# LargeDummyDevice register map
File version: 1.0
Registers are 32-bit, read-write, no defined reset value unless marked. A register's access mark holds for its fields unless they carry their own. Offsets are from the block's base; [hi:lo] are bit positions.

## PERIPHERAL_94
Base 0x4005D000
0x04 REG_1 — Register 1
  [35:31] FIELD_3, [33:31] FIELD_19, [30:28] FIELD_22, [30:27] FIELD_1, [28:26] FIELD_12, [28:26] FIELD_14, [28:25] FIELD_15, [26:23] FIELD_18, [27:23] FIELD_24, [22:20] FIELD_7, [22:19] FIELD_4, [23:19] FIELD_16, [20:16] FIELD_17, [17:13] FIELD_9, [14:12] FIELD_5, [15:12] FIELD_21, [12] FIELD_23, [15:11] FIELD_8, [14:10] FIELD_6, [11:8] FIELD_20, [10:7] FIELD_2, [5:4] FIELD_10, [7:4] FIELD_13, [7:3] FIELD_11
0x08 REG_2 — Register 2
  [32:30] FIELD_9, [31:29] FIELD_19, [29:28] FIELD_6, [30:28] FIELD_20, [29:25] FIELD_14, [24] FIELD_13, [24:23] FIELD_4, [24:23] FIELD_12, [27:23] FIELD_15, [25:22] FIELD_1, [24:21] FIELD_18, [20] FIELD_5, [20:19] FIELD_17, [17:16] FIELD_3, [15:14] FIELD_21, [7:6] FIELD_11, [6] FIELD_16, [6:5] FIELD_7, [4] FIELD_10, [1] FIELD_8, [2:0] FIELD_2
0x0C REG_3 — Register 3
  [29] FIELD_9, [29:28] FIELD_6, [29:26] FIELD_5, [25:24] FIELD_3, [24] FIELD_13, [23:22] FIELD_10, [25:22] FIELD_15, [22:21] FIELD_18, [17] FIELD_7, [17] FIELD_21, [17:16] FIELD_8, [18:16] FIELD_19, [15:14] FIELD_16, [12:10] FIELD_1, [14:10] FIELD_2, [10] FIELD_11, [10:6] FIELD_20, [5:3] FIELD_4, [3] FIELD_12, [4:3] FIELD_14, [2:0] FIELD_17
0x10 REG_4 — Register 4
  [33:31] FIELD_13, [30] FIELD_7, [29:27] FIELD_4, [28:26] FIELD_3, [25:23] FIELD_14, [22] FIELD_12, [20:19] FIELD_16, [17] FIELD_2, [18:14] FIELD_5, [18:14] FIELD_9, [14] FIELD_15, [14:12] FIELD_8, [13:9] FIELD_6, [12:9] FIELD_18, [8:6] FIELD_17, [5:3] FIELD_1, [4:2] FIELD_10, [0] FIELD_11
0x14 REG_5 — Register 5
  [31] FIELD_6, [28] FIELD_18, [29:27] FIELD_21, [27:26] FIELD_4, [27:26] FIELD_22, [25:24] FIELD_8, [28:24] FIELD_23, [24] FIELD_25, [23:22] FIELD_7, [25:21] FIELD_9, [24:20] FIELD_14, [23:20] FIELD_16, [23:20] FIELD_17, [22:20] FIELD_20, [22:19] FIELD_19, [21:18] FIELD_13, [19:18] FIELD_24, [21:17] FIELD_10, [20:17] FIELD_12, [16:13] FIELD_2, [15:12] FIELD_3, [13:12] FIELD_5, [8] FIELD_15, [0] FIELD_1, [3:0] FIELD_11
0x18 REG_6 — Register 6
  [31:30] FIELD_11, [28] FIELD_8, [27] FIELD_3, [24] FIELD_1, [26:24] FIELD_12, [18:16] FIELD_13, [16:15] FIELD_7, [14:12] FIELD_5, [13:11] FIELD_2, [8:7] FIELD_4, [7:6] FIELD_14, [6:2] FIELD_10, [3:1] FIELD_9, [1:0] FIELD_6
0x1C REG_7 — Register 7
  [31:27] FIELD_5, [29:26] FIELD_6, [27:23] FIELD_8, [20:19] FIELD_9, [21:17] FIELD_2, [19:16] FIELD_3, [19:16] FIELD_4, [14:10] FIELD_10, [9:5] FIELD_11, [6:3] FIELD_1, [4:2] FIELD_7
0x20 REG_8 — Register 8
  [33:30] FIELD_7, [28:25] FIELD_2, [26:23] FIELD_1, [23:21] FIELD_6, [24:21] FIELD_8, [19:17] FIELD_5, [17:16] FIELD_3, [10] FIELD_4, [10:6] FIELD_9
0x24 REG_9 — Register 9
  [25] FIELD_8, [23:22] FIELD_20, [23:20] FIELD_1, [21:18] FIELD_22, [18:17] FIELD_2, [18:17] FIELD_3, [19:17] FIELD_10, [19:17] FIELD_11, [19:15] FIELD_6, [10:9] FIELD_9, [12:8] FIELD_15, [10:8] FIELD_17, [10:8] FIELD_19, [9:6] FIELD_16, [6:5] FIELD_14, [7:4] FIELD_5, [6:3] FIELD_4, [6:3] FIELD_12, [4:3] FIELD_13, [5:3] FIELD_21, [3:2] FIELD_7, [4:1] FIELD_18
0x28 REG_10 — Register 10
  [35:31] FIELD_2, [33:31] FIELD_13, [32:31] FIELD_19, [33:29] FIELD_29, [28:27] FIELD_26, [25:24] FIELD_8, [24] FIELD_15, [24:23] FIELD_9, [23:20] FIELD_7, [23:20] FIELD_12, [20] FIELD_27, [20:19] FIELD_20, [20:18] FIELD_5, [17] FIELD_11, [19:16] FIELD_6, [20:16] FIELD_22, [18:15] FIELD_18, [16:12] FIELD_21, [11] FIELD_4, [14:11] FIELD_10, [14:11] FIELD_16, [15:11] FIELD_30, [11:10] FIELD_3, [10:6] FIELD_25, [6] FIELD_28, [7:4] FIELD_1, [6:4] FIELD_23, [6:2] FIELD_14, [5:1] FIELD_24, [3:0] FIELD_17
0x2C REG_11 — Register 11
  [31] FIELD_11, [33:30] FIELD_1, [34:30] FIELD_20, [28:26] FIELD_7, [29:26] FIELD_12, [30:26] FIELD_17, [28:25] FIELD_3, [27:24] FIELD_5, [24:20] FIELD_15, [18:14] FIELD_4, [17:14] FIELD_19, [14:13] FIELD_9, [12] FIELD_8, [13:12] FIELD_13, [13:10] FIELD_10, [10:8] FIELD_21, [7] FIELD_14, [7:6] FIELD_18, [9:6] FIELD_22, [5:4] FIELD_6, [2] FIELD_16, [3:0] FIELD_2
0x30 REG_12 — Register 12
  [34:31] FIELD_10, [30:27] FIELD_4, [28:27] FIELD_11, [27] FIELD_13, [28:24] FIELD_23, [24:22] FIELD_6, [21] FIELD_3, [23:21] FIELD_18, [20:19] FIELD_5, [19:18] FIELD_19, [18:17] FIELD_9, [16:12] FIELD_21, [12:10] FIELD_22, [12:9] FIELD_15, [11:8] FIELD_14, [7:5] FIELD_1, [6:5] FIELD_2, [8:4] FIELD_7, [4] FIELD_8, [5:4] FIELD_16, [2] FIELD_17, [3:1] FIELD_12, [1:0] FIELD_20
0x34 REG_13 — Register 13
  [32:30] FIELD_3, [33:30] FIELD_11, [30:27] FIELD_1, [27] FIELD_4, [29:27] FIELD_12, [21:20] FIELD_7, [20:19] FIELD_9, [20:18] FIELD_6, [21:18] FIELD_14, [18:17] FIELD_5, [16] FIELD_10, [18:16] FIELD_13, [15:11] FIELD_2, [5:3] FIELD_8
0x38 REG_14 — Register 14
  [31] FIELD_2, [35:31] FIELD_11, [33:31] FIELD_18, [31:28] FIELD_6, [32:28] FIELD_8, [29:28] FIELD_9, [32:28] FIELD_10, [28] FIELD_13, [27] FIELD_4, [28:26] FIELD_21, [26:24] FIELD_12, [22] FIELD_24, [23:21] FIELD_1, [18] FIELD_20, [15] FIELD_14, [18:15] FIELD_17, [14:13] FIELD_15, [13:11] FIELD_3, [10:9] FIELD_16, [11:9] FIELD_23, [6:5] FIELD_25, [7:4] FIELD_19, [4] FIELD_22, [7:3] FIELD_5, [2] FIELD_7
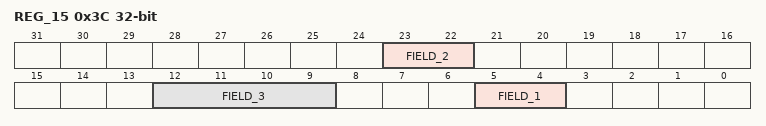
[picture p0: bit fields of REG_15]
0x3C REG_15 — Register 15
  [23:22] FIELD_2, [12:9] FIELD_3, [5:4] FIELD_1
0x40 REG_16 — Register 16
  [31] FIELD_6, [33:30] FIELD_8, [34:30] FIELD_16, [31:28] FIELD_15, [30:27] FIELD_2, [28:27] FIELD_7, [26:25] FIELD_10, [28:25] FIELD_19, [25:23] FIELD_22, [22:21] FIELD_4, [23:21] FIELD_11, [21] FIELD_20, [20] FIELD_12, [22:20] FIELD_13, [18] FIELD_5, [18] FIELD_17, [19:17] FIELD_21, [20:16] FIELD_23, [19:16] FIELD_24, [19:15] FIELD_1, [16:14] FIELD_26, [17:13] FIELD_9, [16:13] FIELD_28, [11] FIELD_29, [5] FIELD_27, [6:3] FIELD_25, [5:2] FIELD_18, [2:1] FIELD_3, [4:0] FIELD_14
0x44 REG_17 — Register 17
  [33:31] FIELD_5, [34:30] FIELD_7, [30] FIELD_8, [31:29] FIELD_2, [31:27] FIELD_20, [27:25] FIELD_9, [23] FIELD_13, [19:16] FIELD_3, [18:15] FIELD_21, [17:13] FIELD_10, [15:12] FIELD_1, [13:10] FIELD_12, [11:10] FIELD_17, [7] FIELD_14, [6] FIELD_4, [7:6] FIELD_15, [8:6] FIELD_18, [9:6] FIELD_19, [5:4] FIELD_16, [6:2] FIELD_6, [2] FIELD_11
0x48 REG_18 — Register 18
  [31:28] FIELD_6, [28:26] FIELD_5, [28:24] FIELD_4, [23] FIELD_8, [26:22] FIELD_7, [11:8] FIELD_1, [7:4] FIELD_2, [4] FIELD_3
0x4C REG_19 — Register 19
  [34:31] FIELD_5, [32:28] FIELD_12, [30:28] FIELD_14, [24:22] FIELD_6, [25:21] FIELD_10, [24:20] FIELD_4, [20] FIELD_13, [19:18] FIELD_1, [16:14] FIELD_2, [15:11] FIELD_16, [10:8] FIELD_9, [7:5] FIELD_3, [8:5] FIELD_7, [4] FIELD_15, [4:1] FIELD_8, [2:1] FIELD_11
0x50 REG_20 — Register 20
  [33:31] FIELD_8, [30] FIELD_22, [29] FIELD_30, [29:28] FIELD_29, [26] FIELD_18, [25] FIELD_11, [28:25] FIELD_12, [24:21] FIELD_7, [20] FIELD_16, [21:20] FIELD_23, [21:17] FIELD_13, [17] FIELD_25, [15] FIELD_3, [18:15] FIELD_14, [19:15] FIELD_27, [18:14] FIELD_2, [17:14] FIELD_21, [17:13] FIELD_19, [15:13] FIELD_28, [14:11] FIELD_17, [14:10] FIELD_6, [12:10] FIELD_9, [13:9] FIELD_10, [10:9] FIELD_15, [8:7] FIELD_24, [10:6] FIELD_1, [7:6] FIELD_26, [8:6] FIELD_31, [8:4] FIELD_4, [8:4] FIELD_20, [5:1] FIELD_5
0x54 REG_21 — Register 21
  [32:28] FIELD_10, [30:27] FIELD_16, [27:25] FIELD_20, [26:24] FIELD_4, [27:24] FIELD_17, [24:23] FIELD_21, [23:21] FIELD_7, [19] FIELD_1, [21:19] FIELD_12, [21:19] FIELD_18, [18:17] FIELD_13, [19:17] FIELD_14, [16:13] FIELD_2, [11] FIELD_11, [10] FIELD_5, [9] FIELD_8, [8] FIELD_6, [8:7] FIELD_22, [6:5] FIELD_3, [6:4] FIELD_15, [6:3] FIELD_9, [6:3] FIELD_19
0x58 REG_22 — Register 22
  [33:31] FIELD_3, [30:28] FIELD_1, [22] FIELD_2
0x5C REG_23 — Register 23
  [35:31] FIELD_9, [29] FIELD_2, [27] FIELD_10, [23:22] FIELD_1, [26:22] FIELD_3, [21:20] FIELD_4, [16] FIELD_5, [9:5] FIELD_8, [7:4] FIELD_7, [2:1] FIELD_6
0x60 REG_24 — Register 24
  [29:28] FIELD_17, [31:27] FIELD_12, [27:23] FIELD_4, [27:23] FIELD_7, [26:23] FIELD_14, [21:20] FIELD_13, [22:20] FIELD_15, [17:16] FIELD_5, [16:15] FIELD_9, [14] FIELD_6, [15:14] FIELD_10, [13:10] FIELD_2, [11:8] FIELD_1, [8] FIELD_3, [7:6] FIELD_11, [5:4] FIELD_8, [3:1] FIELD_16
0x64 REG_25 — Register 25
  [31] FIELD_12, [32:31] FIELD_17, [34:30] FIELD_15, [31:30] FIELD_27, [32:29] FIELD_6, [33:29] FIELD_11, [30:28] FIELD_7, [29:28] FIELD_21, [30:27] FIELD_22, [27:24] FIELD_5, [22] FIELD_13, [24:22] FIELD_30, [23:20] FIELD_8, [23:20] FIELD_9, [21:19] FIELD_26, [20:18] FIELD_16, [17] FIELD_3, [20:17] FIELD_4, [19:17] FIELD_28, [15] FIELD_2, [19:15] FIELD_19, [18:15] FIELD_25, [16:14] FIELD_24, [10] FIELD_1, [13:9] FIELD_23, [8:7] FIELD_18, [9:5] FIELD_29, [4:3] FIELD_20, [0] FIELD_10, [1:0] FIELD_14
0x68 REG_26 — Register 26
  [32:31] FIELD_11, [34:31] FIELD_16, [31:29] FIELD_8, [27] FIELD_12, [30:26] FIELD_20, [26:24] FIELD_4, [24] FIELD_17, [27:23] FIELD_3, [27:23] FIELD_10, [22] FIELD_5, [22] FIELD_15, [17:14] FIELD_19, [15:13] FIELD_6, [12] FIELD_7, [11] FIELD_13, [12:10] FIELD_21, [12:9] FIELD_9, [8:4] FIELD_18, [6:2] FIELD_1, [5:1] FIELD_2, [4:0] FIELD_14
0x6C REG_27 — Register 27
  [30:29] FIELD_24, [30:27] FIELD_15, [26:25] FIELD_17, [27:25] FIELD_20, [25:24] FIELD_22, [27:24] FIELD_23, [21:19] FIELD_12, [22:19] FIELD_21, [21:19] FIELD_25, [21:17] FIELD_14, [19:15] FIELD_26, [18:14] FIELD_19, [14:10] FIELD_2, [12:10] FIELD_16, [11:9] FIELD_6, [11:7] FIELD_1, [11:7] FIELD_4, [10:7] FIELD_5, [8:7] FIELD_11, [7:6] FIELD_8, [6] FIELD_18, [5] FIELD_7, [7:5] FIELD_13, [5:4] FIELD_10, [3] FIELD_3, [6:2] FIELD_9
0x70 REG_28 — Register 28
  [19] FIELD_1
0x74 REG_29 — Register 29
  [32:28] FIELD_11, [29:26] FIELD_1, [30:26] FIELD_7, [22:18] FIELD_2, [21:18] FIELD_8, [21:17] FIELD_6, [17] FIELD_9, [15] FIELD_5, [10] FIELD_4, [10:8] FIELD_10, [10:6] FIELD_3
0x78 REG_30 — Register 30
  [32:30] FIELD_2, [27:26] FIELD_5, [25:22] FIELD_6, [24:20] FIELD_1, [10] FIELD_4, [4] FIELD_3
0x7C REG_31 — Register 31
  [32:31] FIELD_1, [34:31] FIELD_2, [31:28] FIELD_4, [30:26] FIELD_8, [22:20] FIELD_6, [22:18] FIELD_5, [17:14] FIELD_7, [13:11] FIELD_9, [11:8] FIELD_3
0x80 REG_32 — Register 32
  [22:20] FIELD_1
0x84 REG_33 — Register 33
  [31] FIELD_14, [33:30] FIELD_3, [30] FIELD_7, [30] FIELD_15, [32:30] FIELD_19, [28] FIELD_24, [27:25] FIELD_17, [25] FIELD_22, [26:24] FIELD_5, [24] FIELD_11, [28:24] FIELD_21, [22:21] FIELD_13, [21:20] FIELD_8, [23:19] FIELD_9, [22:19] FIELD_23, [18] FIELD_1, [21:18] FIELD_16, [15:12] FIELD_4, [8] FIELD_10, [7:5] FIELD_18, [7:4] FIELD_12, [7:3] FIELD_20, [5:2] FIELD_6, [2:0] FIELD_2
0x88 REG_34 — Register 34
  [31] FIELD_24, [29] FIELD_29, [31:28] FIELD_5, [28] FIELD_26, [27:26] FIELD_9, [29:26] FIELD_25, [26:24] FIELD_17, [23:21] FIELD_10, [25:21] FIELD_11, [19] FIELD_4, [21:19] FIELD_21, [19:18] FIELD_18, [19:17] FIELD_13, [16] FIELD_7, [18:15] FIELD_27, [13] FIELD_14, [17:13] FIELD_23, [13:12] FIELD_15, [13:9] FIELD_8, [12:9] FIELD_20, [10:9] FIELD_22, [9] FIELD_30, [11:8] FIELD_16, [6] FIELD_19, [6:5] FIELD_28, [4:3] FIELD_1, [7:3] FIELD_3, [4:3] FIELD_12, [1] FIELD_2, [3:1] FIELD_6
0x8C REG_35 — Register 35
  [26] FIELD_19, [29:25] FIELD_7, [26:25] FIELD_17, [24] FIELD_6, [25:24] FIELD_9, [24:22] FIELD_5, [22:21] FIELD_8, [23:20] FIELD_11, [18] FIELD_2, [19:18] FIELD_10, [16:15] FIELD_15, [13:12] FIELD_1, [12:11] FIELD_4, [15:11] FIELD_12, [7:6] FIELD_13, [10:6] FIELD_14, [7:4] FIELD_3, [4:1] FIELD_16, [2:0] FIELD_18
0x90 REG_36 — Register 36
  [32:31] FIELD_6, [31:27] FIELD_23, [30:26] FIELD_27, [27:25] FIELD_11, [29:25] FIELD_19, [27:25] FIELD_21, [23] FIELD_24, [25:22] FIELD_14, [25:22] FIELD_25, [20] FIELD_1, [23:20] FIELD_4, [23:20] FIELD_9, [19] FIELD_20, [21:18] FIELD_12, [19:17] FIELD_2, [20:17] FIELD_16, [11] FIELD_10, [12:11] FIELD_13, [15:11] FIELD_15, [9] FIELD_17, [7] FIELD_7, [9:7] FIELD_8, [6:3] FIELD_5, [3:1] FIELD_3, [4:1] FIELD_18, [3:1] FIELD_26, [1:0] FIELD_22
0x94 REG_37 — Register 37
  [27:24] FIELD_1
0x98 REG_38 — Register 38
  [32:29] FIELD_1, [29] FIELD_2, [28:25] FIELD_9, [16] FIELD_6, [11] FIELD_8, [13:10] FIELD_7, [9:5] FIELD_4, [7:5] FIELD_5, [4:0] FIELD_3
0x9C REG_39 — Register 39
  [31] FIELD_7, [28:26] FIELD_3, [29:25] FIELD_12, [27:24] FIELD_4, [25:24] FIELD_11, [24:23] FIELD_5, [24:21] FIELD_10, [19] FIELD_6, [12:10] FIELD_1, [7:5] FIELD_8, [6:4] FIELD_9, [2] FIELD_2
0xA0 REG_40 — Register 40
  [15:11] FIELD_1
0xA4 REG_41 — Register 41
  [34:31] FIELD_21, [31:29] FIELD_4, [33:29] FIELD_9, [32:28] FIELD_18, [28:27] FIELD_12, [30:27] FIELD_25, [24] FIELD_11, [24] FIELD_23, [26:22] FIELD_14, [23:22] FIELD_24, [23:20] FIELD_5, [22:19] FIELD_10, [20:17] FIELD_17, [17:13] FIELD_16, [14:13] FIELD_20, [16:12] FIELD_8, [15:11] FIELD_26, [9:6] FIELD_7, [9:5] FIELD_2, [6:4] FIELD_3, [5:2] FIELD_13, [5:2] FIELD_19, [5:1] FIELD_1, [1] FIELD_6, [4:0] FIELD_15, [0] FIELD_22
